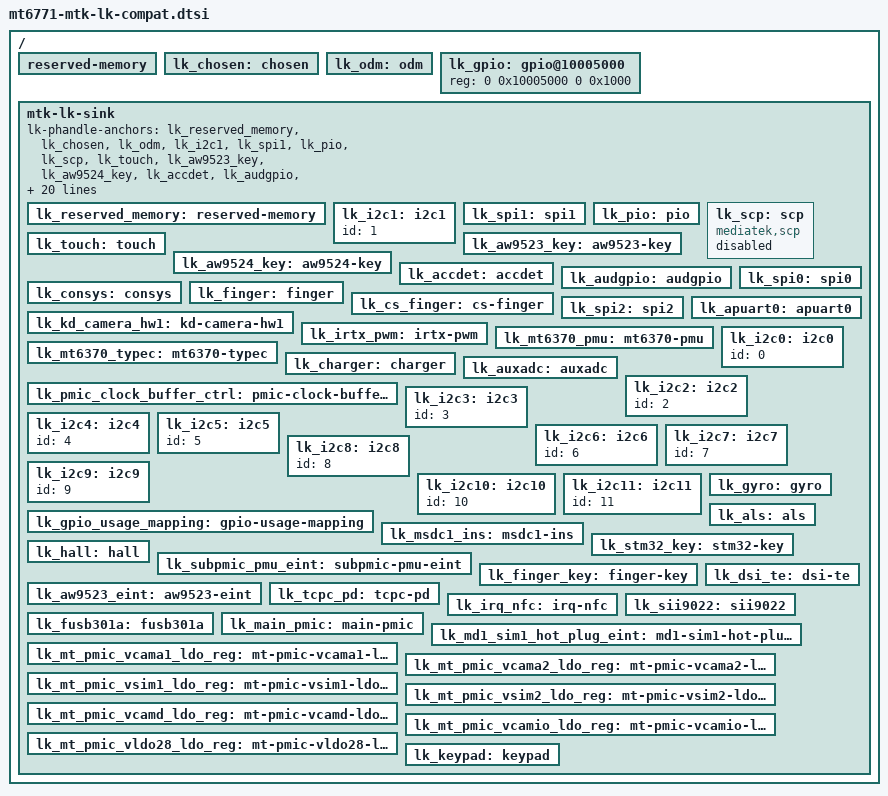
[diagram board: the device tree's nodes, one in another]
// SPDX-License-Identifier: (GPL-2.0-only OR MIT)
/*
 * GENERATED by tools/gen-lk-compat-dtsi.py - do not edit by hand.
 *
 * MediaTek LK (Planet Cosmo, k71v1_64_bsp, 2020-07-06) compatibility layer.
 * Include this LAST from the board .dts. What LK demands of the appended DTB
 * (each one is an ASSERT or while(1) in LK when violated):
 *
 *  1. The vendor `dtbo` overlay must apply: /__symbols__ must resolve every
 *     label in the overlay's __fixups__, and each target needs a phandle.
 *  2. /chosen/bootargs must exist.
 *  3. A node with compatible "mediatek,scp" must exist.
 *  4. /reserved-memory must exist, and no child with a static `reg` may
 *     overlap a region LK reserved itself (ATF, TEE, SSPM, SPM, SCP, modem,
 *     framebuffer...). LK appends those as mblock-N-* nodes on its own.
 *  5. /memory and /chosen must exist (LK rewrites reg/bootargs/initrd).
 */

/ {
	reserved-memory {
		/* LK appends the real ones (mblock-N-*); static copies make it hang. */
		/delete-node/ atf@54600000;
		/delete-node/ spm@77ff0000;
		/delete-node/ sspm@7ff00000;
		/delete-node/ scp@9f900000;
		/delete-node/ dramc@bffff000;
		/delete-node/ tee@edb00000;
	};

	lk_chosen: chosen { };

	/* LK reads LED/backlight config from /odm/led@N (vendor overlay fills it) */
	lk_odm: odm { };

	/* LK applies gpio_init_default from here (vendor overlay fills it) */
	lk_gpio: gpio@10005000 {
		reg = <0 0x10005000 0 0x1000>;
	};

	/* No compatible: the kernel never creates devices at or below this node. */
	mtk-lk-sink {
		/* forces dtc to emit a phandle for every overlay target */
		lk-phandle-anchors = <&lk_reserved_memory
			&lk_chosen
			&lk_odm
			&lk_i2c1
			&lk_spi1
			&lk_pio
			&lk_scp
			&lk_touch
			&lk_aw9523_key
			&lk_aw9524_key
			&lk_accdet
			&lk_audgpio
			&lk_consys
			&lk_spi0
			&lk_finger
			&lk_cs_finger
			&lk_spi2
			&lk_kd_camera_hw1
			&lk_apuart0
			&lk_irtx_pwm
			&lk_mt6370_pmu
			&lk_mt6370_typec
			&lk_charger
			&lk_auxadc
			&lk_pmic_clock_buffer_ctrl
			&lk_i2c0
			&lk_i2c2
			&lk_i2c3
			&lk_i2c4
			&lk_i2c5
			&lk_i2c6
			&lk_i2c7
			&lk_i2c8
			&lk_i2c9
			&lk_i2c10
			&lk_i2c11
			&lk_gpio_usage_mapping
			&lk_gpio
			&lk_msdc1_ins
			&lk_gyro
			&lk_als
			&lk_stm32_key
			&lk_hall
			&lk_subpmic_pmu_eint
			&lk_finger_key
			&lk_aw9523_eint
			&lk_tcpc_pd
			&lk_dsi_te
			&lk_irq_nfc
			&lk_sii9022
			&lk_fusb301a
			&lk_main_pmic
			&lk_md1_sim1_hot_plug_eint
			&lk_mt_pmic_vcama1_ldo_reg
			&lk_mt_pmic_vcama2_ldo_reg
			&lk_mt_pmic_vsim1_ldo_reg
			&lk_mt_pmic_vsim2_ldo_reg
			&lk_mt_pmic_vcamd_ldo_reg
			&lk_mt_pmic_vcamio_ldo_reg
			&lk_mt_pmic_vldo28_ldo_reg
			&lk_keypad>;

		lk_reserved_memory: reserved-memory {};
		lk_i2c1: i2c1 {
			id = <1>;
		};
		lk_spi1: spi1 {};
		lk_pio: pio {};
		lk_scp: scp {
			compatible = "mediatek,scp";
			status = "disabled";
		};
		lk_touch: touch {};
		lk_aw9523_key: aw9523-key {};
		lk_aw9524_key: aw9524-key {};
		lk_accdet: accdet {};
		lk_audgpio: audgpio {};
		lk_consys: consys {};
		lk_spi0: spi0 {};
		lk_finger: finger {};
		lk_cs_finger: cs-finger {};
		lk_spi2: spi2 {};
		lk_kd_camera_hw1: kd-camera-hw1 {};
		lk_apuart0: apuart0 {};
		lk_irtx_pwm: irtx-pwm {};
		lk_mt6370_pmu: mt6370-pmu {};
		lk_mt6370_typec: mt6370-typec {};
		lk_charger: charger {};
		lk_auxadc: auxadc {};
		lk_pmic_clock_buffer_ctrl: pmic-clock-buffer-ctrl {};
		lk_i2c0: i2c0 {
			id = <0>;
		};
		lk_i2c2: i2c2 {
			id = <2>;
		};
		lk_i2c3: i2c3 {
			id = <3>;
		};
		lk_i2c4: i2c4 {
			id = <4>;
		};
		lk_i2c5: i2c5 {
			id = <5>;
		};
		lk_i2c6: i2c6 {
			id = <6>;
		};
		lk_i2c7: i2c7 {
			id = <7>;
		};
		lk_i2c8: i2c8 {
			id = <8>;
		};
		lk_i2c9: i2c9 {
			id = <9>;
		};
		lk_i2c10: i2c10 {
			id = <10>;
		};
		lk_i2c11: i2c11 {
			id = <11>;
		};
		lk_gpio_usage_mapping: gpio-usage-mapping {};
		lk_msdc1_ins: msdc1-ins {};
		lk_gyro: gyro {};
		lk_als: als {};
		lk_stm32_key: stm32-key {};
		lk_hall: hall {};
		lk_subpmic_pmu_eint: subpmic-pmu-eint {};
		lk_finger_key: finger-key {};
		lk_aw9523_eint: aw9523-eint {};
		lk_tcpc_pd: tcpc-pd {};
		lk_dsi_te: dsi-te {};
		lk_irq_nfc: irq-nfc {};
		lk_sii9022: sii9022 {};
		lk_fusb301a: fusb301a {};
		lk_main_pmic: main-pmic {};
		lk_md1_sim1_hot_plug_eint: md1-sim1-hot-plug-eint {};
		lk_mt_pmic_vcama1_ldo_reg: mt-pmic-vcama1-ldo-reg {};
		lk_mt_pmic_vcama2_ldo_reg: mt-pmic-vcama2-ldo-reg {};
		lk_mt_pmic_vsim1_ldo_reg: mt-pmic-vsim1-ldo-reg {};
		lk_mt_pmic_vsim2_ldo_reg: mt-pmic-vsim2-ldo-reg {};
		lk_mt_pmic_vcamd_ldo_reg: mt-pmic-vcamd-ldo-reg {};
		lk_mt_pmic_vcamio_ldo_reg: mt-pmic-vcamio-ldo-reg {};
		lk_mt_pmic_vldo28_ldo_reg: mt-pmic-vldo28-ldo-reg {};
		lk_keypad: keypad {};
	};

	__symbols__ {
		reserved_memory = "/mtk-lk-sink/reserved-memory";
		chosen = "/chosen";
		odm = "/odm";
		i2c1 = "/mtk-lk-sink/i2c1";
		spi1 = "/mtk-lk-sink/spi1";
		pio = "/mtk-lk-sink/pio";
		scp = "/mtk-lk-sink/scp";
		touch = "/mtk-lk-sink/touch";
		aw9523_key = "/mtk-lk-sink/aw9523-key";
		aw9524_key = "/mtk-lk-sink/aw9524-key";
		accdet = "/mtk-lk-sink/accdet";
		audgpio = "/mtk-lk-sink/audgpio";
		consys = "/mtk-lk-sink/consys";
		spi0 = "/mtk-lk-sink/spi0";
		finger = "/mtk-lk-sink/finger";
		cs_finger = "/mtk-lk-sink/cs-finger";
		spi2 = "/mtk-lk-sink/spi2";
		kd_camera_hw1 = "/mtk-lk-sink/kd-camera-hw1";
		apuart0 = "/mtk-lk-sink/apuart0";
		irtx_pwm = "/mtk-lk-sink/irtx-pwm";
		mt6370_pmu = "/mtk-lk-sink/mt6370-pmu";
		mt6370_typec = "/mtk-lk-sink/mt6370-typec";
		charger = "/mtk-lk-sink/charger";
		auxadc = "/mtk-lk-sink/auxadc";
		pmic_clock_buffer_ctrl = "/mtk-lk-sink/pmic-clock-buffer-ctrl";
		i2c0 = "/mtk-lk-sink/i2c0";
		i2c2 = "/mtk-lk-sink/i2c2";
		i2c3 = "/mtk-lk-sink/i2c3";
		i2c4 = "/mtk-lk-sink/i2c4";
		i2c5 = "/mtk-lk-sink/i2c5";
		i2c6 = "/mtk-lk-sink/i2c6";
		i2c7 = "/mtk-lk-sink/i2c7";
		i2c8 = "/mtk-lk-sink/i2c8";
		i2c9 = "/mtk-lk-sink/i2c9";
		i2c10 = "/mtk-lk-sink/i2c10";
		i2c11 = "/mtk-lk-sink/i2c11";
		gpio_usage_mapping = "/mtk-lk-sink/gpio-usage-mapping";
		gpio = "/gpio@10005000";
		msdc1_ins = "/mtk-lk-sink/msdc1-ins";
		gyro = "/mtk-lk-sink/gyro";
		als = "/mtk-lk-sink/als";
		stm32_key = "/mtk-lk-sink/stm32-key";
		hall = "/mtk-lk-sink/hall";
		subpmic_pmu_eint = "/mtk-lk-sink/subpmic-pmu-eint";
		finger_key = "/mtk-lk-sink/finger-key";
		aw9523_eint = "/mtk-lk-sink/aw9523-eint";
		tcpc_pd = "/mtk-lk-sink/tcpc-pd";
		dsi_te = "/mtk-lk-sink/dsi-te";
		irq_nfc = "/mtk-lk-sink/irq-nfc";
		sii9022 = "/mtk-lk-sink/sii9022";
		fusb301a = "/mtk-lk-sink/fusb301a";
		main_pmic = "/mtk-lk-sink/main-pmic";
		md1_sim1_hot_plug_eint = "/mtk-lk-sink/md1-sim1-hot-plug-eint";
		mt_pmic_vcama1_ldo_reg = "/mtk-lk-sink/mt-pmic-vcama1-ldo-reg";
		mt_pmic_vcama2_ldo_reg = "/mtk-lk-sink/mt-pmic-vcama2-ldo-reg";
		mt_pmic_vsim1_ldo_reg = "/mtk-lk-sink/mt-pmic-vsim1-ldo-reg";
		mt_pmic_vsim2_ldo_reg = "/mtk-lk-sink/mt-pmic-vsim2-ldo-reg";
		mt_pmic_vcamd_ldo_reg = "/mtk-lk-sink/mt-pmic-vcamd-ldo-reg";
		mt_pmic_vcamio_ldo_reg = "/mtk-lk-sink/mt-pmic-vcamio-ldo-reg";
		mt_pmic_vldo28_ldo_reg = "/mtk-lk-sink/mt-pmic-vldo28-ldo-reg";
		keypad = "/mtk-lk-sink/keypad";
	};
};
